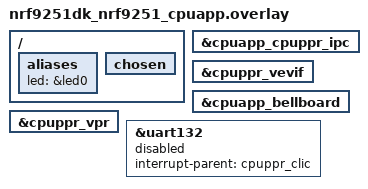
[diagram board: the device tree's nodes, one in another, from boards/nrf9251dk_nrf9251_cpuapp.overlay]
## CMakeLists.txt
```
#
# Copyright (c) 2024 Nordic Semiconductor ASA
#
# SPDX-License-Identifier: LicenseRef-Nordic-5-Clause
#

cmake_minimum_required(VERSION 3.20.0)

find_package(Zephyr REQUIRED HINTS $ENV{ZEPHYR_BASE})

if(NOT SYSBUILD)
  message(FATAL_ERROR
    " This is a multi-image application that should be built using sysbuild.\n"
    " Add --sysbuild argument to west build command to prepare all the images."
  )
endif()

project(idle_ipc)

target_sources(app PRIVATE src/main.c)
```

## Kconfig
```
#
# Copyright (c) 2024 Nordic Semiconductor ASA
#
# SPDX-License-Identifier: LicenseRef-Nordic-5-Clause
#

source "Kconfig.zephyr"
rsource "Kconfig.common"
```

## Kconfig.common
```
#
# Copyright (c) 2024 Nordic Semiconductor ASA
#
# SPDX-License-Identifier: LicenseRef-Nordic-5-Clause
#

config APP_IPC_SERVICE_MESSAGE_LEN
	int "Length of single IPC message in bytes"
	default 100

config TEST_START_DELAY_MS
	int "Delay for test startup [ms]"
	default 0

config SLEEP_TIME_MS
	int "Core sleep time [ms]"
	default 1000
```

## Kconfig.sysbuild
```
#
# Copyright (c) 2024 Nordic Semiconductor ASA
#
# SPDX-License-Identifier: LicenseRef-Nordic-5-Clause
#

choice NETCORE
	default NETCORE_REMOTE

config NETCORE_REMOTE
	bool "Remote image"

endchoice

config NETCORE_IMAGE_NAME
	default "remote" if NETCORE_REMOTE

config NETCORE_IMAGE_PATH
	default "$(ZEPHYR_NRF_MODULE_DIR)/tests/benchmarks/multicore/idle_ipc/remote" if NETCORE_REMOTE

choice PPRCORE
	default PPRCORE_REMOTE if SOC_NRF9251_CPUAPP
	default PPRCORE_NONE

config PPRCORE_REMOTE
	bool "Remote image"

endchoice

config PPRCORE_IMAGE_NAME
	default "remote_ppr" if PPRCORE_REMOTE

config PPRCORE_IMAGE_PATH
	default "$(ZEPHYR_NRF_MODULE_DIR)/tests/benchmarks/multicore/idle_ipc/remote" if PPRCORE_REMOTE

source "share/sysbuild/Kconfig"
```

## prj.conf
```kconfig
# Copyright (c) 2024 Nordic Semiconductor ASA
# SPDX-License-Identifier: LicenseRef-Nordic-5-Clause

CONFIG_LOG_PROCESS_THREAD_PRIORITY=-15
CONFIG_LOG_PROCESS_THREAD_CUSTOM_PRIORITY=y

CONFIG_HEAP_MEM_POOL_SIZE=4096

CONFIG_MBOX=y

CONFIG_IPC_SERVICE=y
CONFIG_IPC_SERVICE_LOG_LEVEL_INF=y

CONFIG_PM=y
CONFIG_PM_DEVICE=y
CONFIG_POWEROFF=y
CONFIG_PM_DEVICE_RUNTIME=y

CONFIG_ASSERT=y

CONFIG_PRINTK=y
CONFIG_LOG=y
CONFIG_CONSOLE=y
CONFIG_UART_CONSOLE=y
```

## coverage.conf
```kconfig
CONFIG_HEAP_MEM_POOL_SIZE=4096
CONFIG_MBOX=y
CONFIG_IPC_SERVICE=y

CONFIG_PM=y
CONFIG_PM_DEVICE=y
CONFIG_PM_DEVICE_RUNTIME=y
CONFIG_POWEROFF=y

CONFIG_BOOT_BANNER=n
CONFIG_NCS_BOOT_BANNER=n
CONFIG_ASSERT=n
CONFIG_CLOCK_CONTROL=n

CONFIG_PRINTK=y
CONFIG_LOG=n
CONFIG_CONSOLE=y
CONFIG_UART_CONSOLE=y

CONFIG_LOG_BUFFER_SIZE=16384
```

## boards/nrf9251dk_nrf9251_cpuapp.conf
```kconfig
#
# Copyright (c) 2026 Nordic Semiconductor ASA
#
# SPDX-License-Identifier: LicenseRef-Nordic-5-Clause
#

# Disable Logs otherwise code will not fit on PPR
CONFIG_BOOT_BANNER=n
CONFIG_NCS_BOOT_BANNER=n

CONFIG_PRINTK=n
CONFIG_LOG=n
CONFIG_CONSOLE=n
CONFIG_UART_CONSOLE=n
```

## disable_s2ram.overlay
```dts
&s2ram {
	status = "disabled";
};

&idle_cache_disabled {
	status = "disabled";
};

&idle_cache_retained {
	status = "disabled";
};
```

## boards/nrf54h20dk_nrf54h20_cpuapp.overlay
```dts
/*
 * Copyright (c) 2025 Nordic Semiconductor ASA
 *
 * SPDX-License-Identifier: LicenseRef-Nordic-5-Clause
 */

/ {
	aliases {
		led = &led0;
		/delete-property/ led1;
	};
};

/delete-node/ &led1;

&gpio6 {
	status = "disabled";
};

&exmif {
	status = "disabled";
};
```

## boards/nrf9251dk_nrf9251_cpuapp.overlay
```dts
/*
 * Copyright (c) 2026 Nordic Semiconductor ASA
 *
 * SPDX-License-Identifier: LicenseRef-Nordic-5-Clause
 */

/ {
	aliases {
		led = &led0;
	};
};

ipc0: &cpuapp_cpuppr_ipc {
	status = "okay";
};

&cpuppr_vevif {
	status = "okay";
};

&cpuapp_bellboard {
	status = "okay";
};

/ {
	chosen {
		/delete-property/ zephyr,bt-hci;
	};
};

&cpuppr_vpr {
	status = "okay";
};

&uart132 {
	status = "reserved";
	interrupt-parent = <&cpuppr_clic>;
};
```

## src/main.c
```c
/*
 * Copyright (c) 2024 Nordic Semiconductor ASA
 *
 * SPDX-License-Identifier: LicenseRef-Nordic-5-Clause
 */

#include <zephyr/kernel.h>
#include <zephyr/device.h>
#include <zephyr/pm/device.h>
#include <zephyr/pm/device_runtime.h>
#include <string.h>
#include <zephyr/logging/log.h>
#include <zephyr/ipc/ipc_service.h>
#include <zephyr/drivers/gpio.h>

#ifdef CONFIG_TEST_EXTRA_STACK_SIZE
#define STACKSIZE (1024 + CONFIG_TEST_EXTRA_STACK_SIZE)
#else
#define STACKSIZE (1024)
#endif
#define NUMBER_OF_MESSAGES_TO_SEND 20
#define IPC_SEND_DEAD_TIME_MS	   1
#define IPC_BOUND_TIMEOUT_MS	   5000

K_THREAD_STACK_DEFINE(ipc0_stack, STACKSIZE);

LOG_MODULE_REGISTER(host, LOG_LEVEL_INF);

static const struct device *const console_dev = DEVICE_DT_GET(DT_CHOSEN(zephyr_console));
static const struct gpio_dt_spec led = GPIO_DT_SPEC_GET(DT_ALIAS(led), gpios);

struct payload {
	unsigned long cnt;
	unsigned long size;
	uint8_t data[];
};

struct payload *p_payload;

static K_SEM_DEFINE(bound_sem, 0, 1);

static void ep_bound(void *priv)
{
	k_sem_give(&bound_sem);
}

static void ep_recv(const void *data, size_t len, void *priv)
{
	uint8_t received_val = *((uint8_t *)data);
	static uint8_t expected_val;

	if ((received_val != expected_val) || (len != CONFIG_APP_IPC_SERVICE_MESSAGE_LEN)) {
		printk("Unexpected message received_val: %d , expected_val: %d\n", received_val,
		       expected_val);
		printk("Test should not enter here\n");
		__ASSERT_NO_MSG(1 == 0);
	}

	expected_val++;
}

static struct ipc_ept_cfg ep_cfg = {
	.name = "ep0",
	.cb = {
		.bound = ep_bound,
		.received = ep_recv,
	},
};

int main(void)
{
	const struct device *ipc0_instance;
	struct ipc_ept ep;
	int ret;
	unsigned long last_cnt = 0;
	unsigned long delta = 0;
	int test_repetitions = 3;

	ret = gpio_is_ready_dt(&led);
	__ASSERT(ret, "Error: GPIO Device not ready");

	ret = gpio_pin_configure_dt(&led, GPIO_OUTPUT_ACTIVE);
	__ASSERT(ret == 0, "Could not configure led GPIO");

	p_payload = (struct payload *)k_malloc(CONFIG_APP_IPC_SERVICE_MESSAGE_LEN);
	if (!p_payload) {
		printk("k_malloc() failure\n");
		__ASSERT_NO_MSG(1 == 0);
	}

	memset(p_payload->data, 0xA5, CONFIG_APP_IPC_SERVICE_MESSAGE_LEN - sizeof(struct payload));

	p_payload->size = CONFIG_APP_IPC_SERVICE_MESSAGE_LEN;
	p_payload->cnt = 0;

	printk("IPC-service %s demo started\n", CONFIG_BOARD_TARGET);

	ipc0_instance = DEVICE_DT_GET(DT_NODELABEL(ipc0));

	ret = ipc_service_open_instance(ipc0_instance);
	if ((ret < 0) && (ret != -EALREADY)) {
		LOG_INF("ipc_service_open_instance() failure (%d)", ret);
		__ASSERT_NO_MSG(ret == 0);
	}

	ret = ipc_service_register_endpoint(ipc0_instance, &ep, &ep_cfg);
	if (ret < 0) {
		printf("ipc_service_register_endpoint() failure (%d)", ret);
		__ASSERT_NO_MSG(ret == 0);
	}

	ret = k_sem_take(&bound_sem, K_MSEC(IPC_BOUND_TIMEOUT_MS));
	if (ret < 0) {
		printf("k_sem_take() failure (%d)", ret);
		__ASSERT_NO_MSG(ret == 0);
	}
	k_msleep(CONFIG_TEST_START_DELAY_MS);

#if defined(CONFIG_COVERAGE)
	printk("Coverage analysis enabled\n");
	while (test_repetitions--)
#else
	while (test_repetitions)
#endif
	{
		printk("Hello\n");
		printk("Send data over IPC\n");

		for (int counter = 0; counter < NUMBER_OF_MESSAGES_TO_SEND; counter++) {
			ret = ipc_service_send(&ep, p_payload, CONFIG_APP_IPC_SERVICE_MESSAGE_LEN);
			if (ret == -ENOMEM) {
				/* No space in the buffer. Retry. */
				continue;
			} else if (ret < 0) {
				printk("send_message(%ld) failed with ret %d\n", p_payload->cnt,
				       ret);
				__ASSERT_NO_MSG(ret == 0);
			}
			k_msleep(IPC_SEND_DEAD_TIME_MS);

			delta = p_payload->cnt - last_cnt;
			printk("Δpkt: %ld (%ld B/pkt) | throughput: %ld bit/s\n", delta,
			       p_payload->size, delta * CONFIG_APP_IPC_SERVICE_MESSAGE_LEN * 8);
			last_cnt = p_payload->cnt;
			p_payload->cnt++;
		}

		printk("Go to sleep (s2ram)\n");
		gpio_pin_set_dt(&led, 0);
		k_msleep(CONFIG_SLEEP_TIME_MS);
		gpio_pin_set_dt(&led, 1);
	}

#if defined(CONFIG_COVERAGE)
	printk("Coverage analysis start\n");
#endif
	return 0;
}
```
